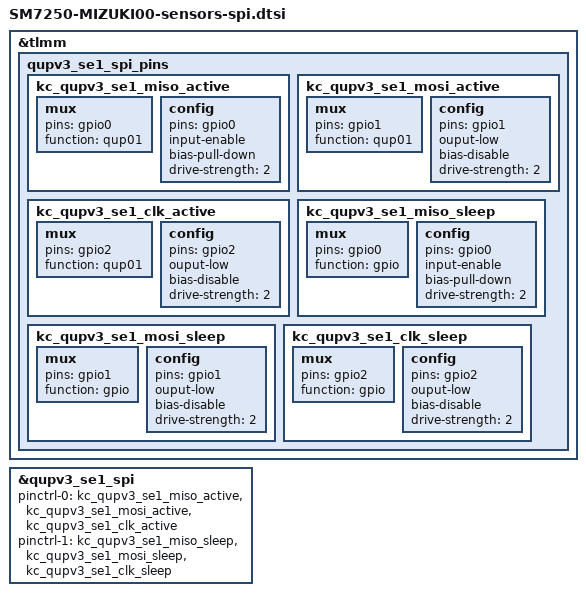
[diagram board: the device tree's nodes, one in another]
/*
 * This software is contributed or developed by KYOCERA Corporation.
 * (C) 2020 KYOCERA Corporation
 *
 * This program is free software; you can redistribute it and/or modify
 * it under the terms of the GNU General Public License version 2 and
 * only version 2 as published by the Free Software Foundation.
 *
 * This program is distributed in the hope that it will be useful,
 * but WITHOUT ANY WARRANTY; without even the implied warranty of
 * MERCHANTABILITY or FITNESS FOR A PARTICULAR PURPOSE.  See the
 * GNU General Public License for more details.
 */

&tlmm{
	qupv3_se1_spi_pins {
		kc_qupv3_se1_miso_active: kc_qupv3_se1_miso_active {
			mux {
				pins = "gpio0";
				function = "qup01";
			};
			config {
				pins = "gpio0";
				input-enable;
				bias-pull-down;
				drive-strength = <2>;
			};
		};

		kc_qupv3_se1_mosi_active: kc_qupv3_se1_mosi_active {
			mux {
				pins = "gpio1";
				function = "qup01";
			};

			config {
				pins = "gpio1";
				ouput-low;
				bias-disable;
				drive-strength = <2>;
			};
		};

		kc_qupv3_se1_clk_active: kc_qupv3_se1_clk_active {
			mux {
				pins = "gpio2";
				function = "qup01";
			};

			config {
				pins = "gpio2";
				ouput-low;
				bias-disable;
				drive-strength = <2>;
			};
		};

		kc_qupv3_se1_miso_sleep: kc_qupv3_se1_miso_sleep {
			mux {
				pins = "gpio0";
				function = "gpio";
			};

			config {
				pins = "gpio0";
				input-enable;
				bias-pull-down;
				drive-strength = <2>;
			};
		};

		kc_qupv3_se1_mosi_sleep: kc_qupv3_se1_mosi_sleep {
			mux {
				pins = "gpio1";
				function = "gpio";
			};

			config {
				pins = "gpio1";
				ouput-low;
				bias-disable;
				drive-strength = <2>;
			};
		};

		kc_qupv3_se1_clk_sleep: kc_qupv3_se1_clk_sleep {
			mux {
				pins = "gpio2";
				function = "gpio";
			};

			config {
				pins = "gpio2";
				ouput-low;
				bias-disable;
				drive-strength = <2>;
			};
		};
	};
};

&qupv3_se1_spi {
	status = "ok";
	pinctrl-0 = <&kc_qupv3_se1_miso_active
				 &kc_qupv3_se1_mosi_active
				 &kc_qupv3_se1_clk_active>;
	pinctrl-1 = <&kc_qupv3_se1_miso_sleep
				 &kc_qupv3_se1_mosi_sleep
				 &kc_qupv3_se1_clk_sleep>;
};
